# R7FA0E303 register map
Vendor: Renesas Electronics Corporation; Series: RA0; File version: 1.00.00
CPU: CM23 r1p0, little endian, no MPU, no FPU, VTOR, 2 interrupt priority bits, 64 interrupts
Registers are 16-bit, read-write, reset 0x0 unless marked. A register's access mark holds for its fields unless they carry their own. Offsets are from the block's base; [hi:lo] are bit positions; 'fields as' and 'values as' point back to an identical list.

## DTC — Data Transfer Controller
Base 0x40005400
0x00 DTCCR 8-bit reset 0x8 — DTC Control Register
  [4] RRS — DTC Transfer Information Read Skip Enable
    0=Transfer information read is not skipped; 1=Transfer information read is skipped when vector numbers match
0x04 DTCVBR 32-bit — DTC Vector Base Register
0x0C DTCST 8-bit — DTC Module Start Register
  [0] DTCST — DTC Module Start
    0=DTC module stopped; 1=DTC module started
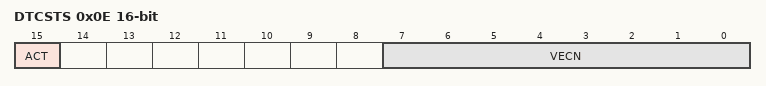
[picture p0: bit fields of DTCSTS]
0x0E DTCSTS ro — DTC Status Register
  [15] ACT — DTC Active Flag
    0=DTC transfer operation is not in progress; 1=DTC transfer operation is in progress
  [7:0] VECN — DTC-Activating Vector Number Monitoring

## DBG — Debug Function
Base 0x4001B000
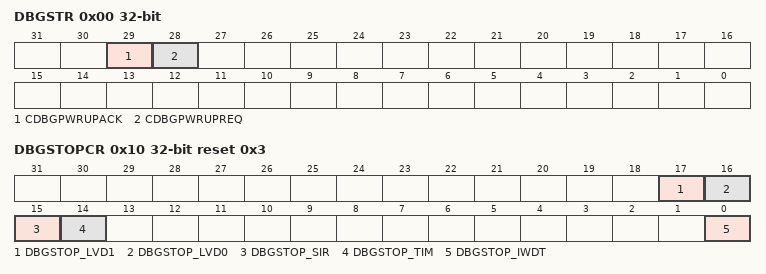
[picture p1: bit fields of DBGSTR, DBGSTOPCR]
0x00 DBGSTR 32-bit ro — Debug Status Register
  [29] CDBGPWRUPACK — Debug Power-up Acknowledge
    0=Debug power-up request is not acknowledged; 1=Debug power-up request is acknowledged
  [28] CDBGPWRUPREQ — Debug Power-up Request
    0=OCD emulator is not requesting debug power up; 1=OCD emulator is requesting debug power up
0x10 DBGSTOPCR 32-bit reset 0x3 — Debug Stop Control Register
  [17] DBGSTOP_LVD1 — Mask Bit for LVD1 Reset/Interrupt
    0=Enable LVD1 reset/interrupt; 1=Mask LVD1 reset/interrupt
  [16] DBGSTOP_LVD0 — Mask Bit for LVD0 Reset
    0=Enable LVD0 reset; 1=Mask LVD0 reset
  [15] DBGSTOP_SIR — Mask Bit for SAU, IICA, PORT_IRQ0-5 Reset/Interrupt in the OCD brake mode. In the OCD break mode, the reset/interrupt is masked and each operation is stopped.
    0=Enable SAU, IICA, PORT_IRQ0 to 5 reset/interrupt; 1=Mask SAU, IICA, PORT_IRQ0 to 5 reset/interrupt
  [14] DBGSTOP_TIM — Mask Bit for TAU, TML32 Reset/Interrupt in the OCD brake mode. In the OCD break mode, the reset/interrupt is masked and each operation is stopped.
    0=Enable TAU, TML32 reset/interrupt; 1=Mask TAU, TML32 reset/interrupt
  [0] DBGSTOP_IWDT — Mask Bit for IWDT Reset/Interrupt in the OCD Run Mode
    0=Enable IWDT reset/interrupt; 1=Mask IWDT reset/interrupt and stop IWDT counter

## IWDT — Independent Watchdog Timer
Base 0x40044400
0x00 IWDTRR 8-bit reset 0xFF — IWDT Refresh Register
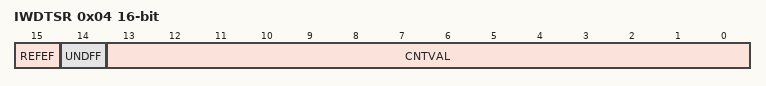
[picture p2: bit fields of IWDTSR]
0x04 IWDTSR — IWDT Status Register
  [15] REFEF — Refresh Error Flag
    0=No refresh error occurred; 1=Refresh error occurred
  [14] UNDFF — Underflow Flag
    0=No underflow occurred; 1=Underflow occurred
  [13:0] CNTVAL ro — Down-counter Value

## MSTP — Module Stop Control
Base 0x40047000
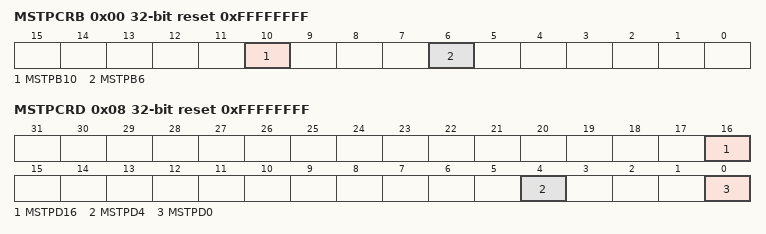
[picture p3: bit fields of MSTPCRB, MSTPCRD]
0x00 MSTPCRB 32-bit reset 0xFFFFFFFF — Module Stop Control Register B
  [10] MSTPB10 — I2C Bus Interface Module Stop
    0=Cancel the module-stop state; 1=Enter the module-stop state
  [6] MSTPB6 — Serial Array Unit 0 Module Stop
    values as MSTPB10
0x04 MSTPCRC 32-bit reset 0xFFFFFFFF — Module Stop Control Register C
  [1] MSTPC1 — Cyclic Redundancy Check Calculator Module Stop
    values as MSTPCRB.MSTPB10
0x08 MSTPCRD 32-bit reset 0xFFFFFFFF — Module Stop Control Register D
  [all] fields
    values as MSTPCRB.MSTPB10
  [16] MSTPD16 — A/D Converter Module Stop
  [4] MSTPD4 — 32-bit Interval Timer Module Stop
  [0] MSTPD0 — Timer Array Unit 0 Module Stop

## CRC — CRC Calculator
Base 0x40074000
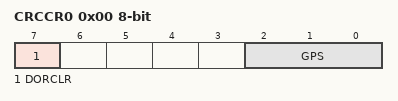
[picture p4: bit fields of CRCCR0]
0x00 CRCCR0 8-bit — CRC Control Register 0
  [7] DORCLR wo — CRCDOR/CRCDOR_HA Register Clear
    0=No effect; 1=Clear the CRCDOR/CRCDOR_HA register
  [2:0] GPS — CRC Generating Polynomial Switching
    3=16-bit CRC-CCITT (X16 + X12 + X5 + 1); 4=32-bit CRC-32 (X32 + X26 + X23 + X22 + X16 + X12 + X11 +X10 + X8 + X7 + X5 + X4 + X2 + X + 1); other=Others (No calculation is executed)
0x04 CRCDIR 32-bit — CRC Data Input Register
0x04 CRCDIR_BY 8-bit (alternate view of CRCDIR) — CRC Data Input Register
0x08 CRCDOR 32-bit — CRC Data Output Register
0x08 CRCDOR_HA (alternate view of CRCDOR) — CRC Data Output Register
